CM_ "IMPORT _common.dbc"
CM_ "IMPORT _bosch_2018.dbc"

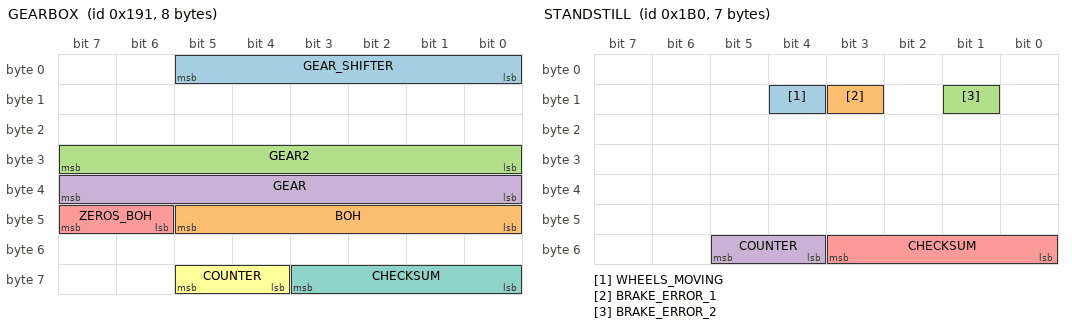
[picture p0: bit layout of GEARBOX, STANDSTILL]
BO_ 401 GEARBOX: 8 PCM
 SG_ GEAR_SHIFTER : 5|6@0+ (1,0) [0|63] "" EON
 SG_ BOH : 45|6@0+ (1,0) [0|63] "" XXX
 SG_ GEAR2 : 31|8@0+ (1,0) [0|1] "" XXX
 SG_ GEAR : 39|8@0+ (1,0) [0|255] "" XXX
 SG_ ZEROS_BOH : 47|2@0+ (1,0) [0|3] "" XXX
 SG_ COUNTER : 61|2@0+ (1,0) [0|3] "" EON
 SG_ CHECKSUM : 59|4@0+ (1,0) [0|15] "" EON

BO_ 432 STANDSTILL: 7 VSA
 SG_ WHEELS_MOVING : 12|1@0+ (1,0) [0|1] "" EON
 SG_ BRAKE_ERROR_1 : 11|1@0+ (1,0) [0|1] "" EON
 SG_ BRAKE_ERROR_2 : 9|1@0+ (1,0) [0|1] "" EON
 SG_ COUNTER : 53|2@0+ (1,0) [0|3] "" EON
 SG_ CHECKSUM : 51|4@0+ (1,0) [0|15] "" EON

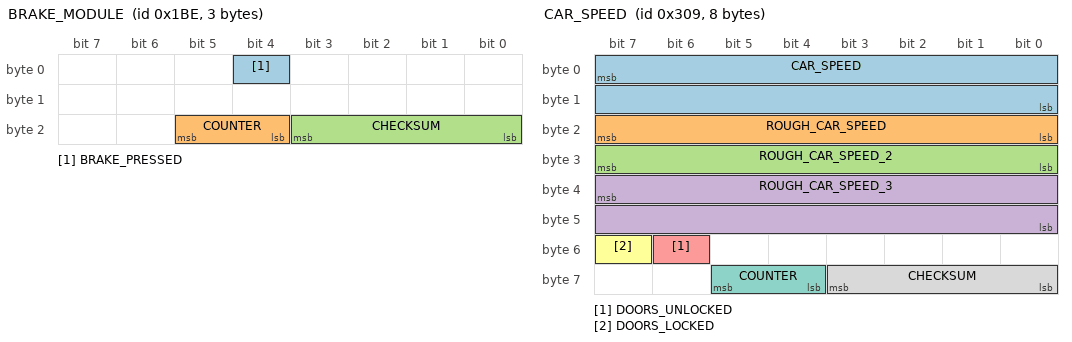
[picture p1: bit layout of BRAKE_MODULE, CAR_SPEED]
BO_ 446 BRAKE_MODULE: 3 VSA
 SG_ BRAKE_PRESSED : 4|1@0+ (1,0) [0|1] "" XXX
 SG_ COUNTER : 21|2@0+ (1,0) [0|3] "" XXX
 SG_ CHECKSUM : 19|4@0+ (1,0) [0|15] "" XXX

BO_ 777 CAR_SPEED: 8 PCM
 SG_ CAR_SPEED : 7|16@0+ (1,0) [0|65535] "" XXX
 SG_ ROUGH_CAR_SPEED : 23|8@0+ (1,0) [0|255] "" XXX
 SG_ ROUGH_CAR_SPEED_2 : 31|8@0+ (1,0) [0|255] "" XXX
 SG_ ROUGH_CAR_SPEED_3 : 39|16@0+ (1,0) [0|65535] "" XXX
 SG_ DOORS_UNLOCKED : 54|1@0+ (1,0) [0|1] "" EON
 SG_ DOORS_LOCKED : 55|1@0+ (1,0) [0|1] "" EON
 SG_ COUNTER : 61|2@0+ (1,0) [0|3] "" XXX
 SG_ CHECKSUM : 59|4@0+ (1,0) [0|15] "" XXX

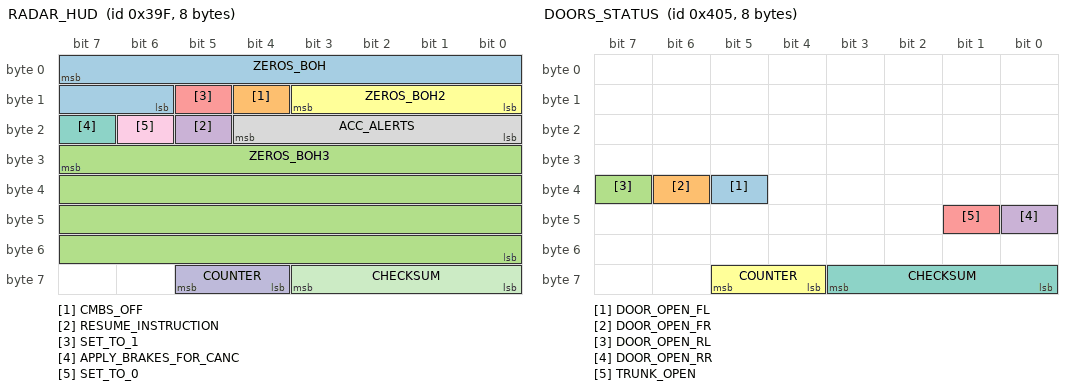
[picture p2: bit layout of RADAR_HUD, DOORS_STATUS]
BO_ 927 RADAR_HUD: 8 RADAR
 SG_ ZEROS_BOH : 7|10@0+ (1,0) [0|127] "" BDY
 SG_ CMBS_OFF : 12|1@0+ (1,0) [0|1] "" BDY
 SG_ ZEROS_BOH3 : 31|32@0+ (1,0) [0|4294967295] "" XXX
 SG_ RESUME_INSTRUCTION : 21|1@0+ (1,0) [0|1] "" XXX
 SG_ SET_TO_1 : 13|1@0+ (1,0) [0|1] "" BDY
 SG_ ZEROS_BOH2 : 11|4@0+ (1,0) [0|1] "" XXX
 SG_ APPLY_BRAKES_FOR_CANC : 23|1@0+ (1,0) [0|1] "" XXX
 SG_ ACC_ALERTS : 20|5@0+ (1,0) [0|1] "" BDY
 SG_ SET_TO_0 : 22|1@0+ (1,0) [0|1] "" XXX
 SG_ COUNTER : 61|2@0+ (1,0) [0|3] "" XXX
 SG_ CHECKSUM : 59|4@0+ (1,0) [0|15] "" XXX

BO_ 1029 DOORS_STATUS: 8 BDY
 SG_ DOOR_OPEN_FL : 37|1@0+ (1,0) [0|1] "" EON
 SG_ DOOR_OPEN_FR : 38|1@0+ (1,0) [0|1] "" EON
 SG_ DOOR_OPEN_RL : 39|1@0+ (1,0) [0|1] "" EON
 SG_ DOOR_OPEN_RR : 40|1@0+ (1,0) [0|1] "" EON
 SG_ TRUNK_OPEN : 41|1@0+ (1,0) [0|1] "" EON
 SG_ COUNTER : 61|2@0+ (1,0) [0|3] "" EON
 SG_ CHECKSUM : 59|4@0+ (1,0) [0|15] "" EON

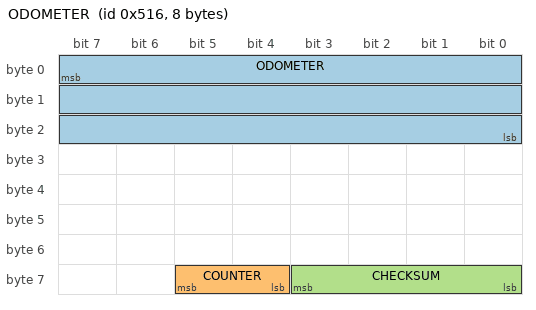
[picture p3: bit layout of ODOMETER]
BO_ 1302 ODOMETER: 8 XXX
 SG_ ODOMETER : 7|24@0+ (1,0) [0|16777215] "km" EON
 SG_ COUNTER : 61|2@0+ (1,0) [0|3] "" EON
 SG_ CHECKSUM : 59|4@0+ (1,0) [0|3] "" EON

CM_ SG_ 450 EPB_STATE "3: On, 2: Disengaging, 1: Engaging, 0: Off";
CM_ SG_ 479 CONTROL_ON "Set to 5 when car is being controlled";
CM_ SG_ 479 RELATED_TO_GAS "bits 7, 3, and 1 set to 1 when gas not applied";
CM_ SG_ 479 GAS_BRAKE "Signed value, negative when braking and positive when applying gas";

VAL_ 401 GEAR_SHIFTER 32 "L" 16 "S" 8 "D" 4 "N" 2 "R" 1 "P" ;
VAL_ 401 GEAR 7 "L" 10 "S" 4 "D" 3 "N" 2 "R" 1 "P" ;

CM_ "CHFFR_METRIC 330 STEER_ANGLE STEER_ANGLE 0.36 180; CHFFR_METRIC 380 ENGINE_RPM ENGINE_RPM 1 0; CHFFR_METRIC 804 ENGINE_TEMPERATURE ENGINE_TEMPERATURE 1 0";
